VERSION ""

NS_ :

BS_:

BU_: Canoe_Debug

BO_ 161 Phase1_Temp_Readings_0x0A1: 8 Vector__XXX
 SG_ tempPhase1_LEFT : 0|32@1- (1,0) [0|0] ""  Canoe_Debug
 SG_ tempPhase1_RIGHT : 32|32@1- (1,0) [0|0] ""  Canoe_Debug

BO_ 162 Phase2_Temp_Readings_0x0A2: 8 Vector__XXX
 SG_ tempPhase2_LEFT : 0|32@1- (1,0) [0|0] ""  Canoe_Debug
 SG_ tempPhase2_RIGHT : 32|32@1- (1,0) [0|0] ""  Canoe_Debug

BO_ 163 V12_Voltage_Phase1_Readings_0x0A3: 8 Vector__XXX
 SG_ voltage12V_bat1_phase1 : 0|32@1- (1,0) [0|0] ""  Canoe_Debug
 SG_ voltage12V_bat2_phase1 : 32|32@1- (1,0) [0|0] ""  Canoe_Debug

BO_ 164 V12_Voltage_Phase2_Readings_0x0A4: 8 Vector__XXX
 SG_ voltage12V_bat1_phase2 : 0|32@1- (1,0) [0|0] ""  Canoe_Debug
 SG_ voltage12V_bat2_phase2 : 32|32@1- (1,0) [0|0] ""  Canoe_Debug

BO_ 165 Phase1_Current_Readings_0X0A5: 8 Vector__XXX
 SG_ current_ph1_in : 0|32@1- (1,0) [0|0] ""  Canoe_Debug
 SG_ current_ph1_out : 32|32@1- (1,0) [0|0] ""  Canoe_Debug

BO_ 166 Phase2_Current_Readings_0X0A6: 8 Vector__XXX
 SG_ current_ph2_in : 0|32@1- (1,0) [0|0] ""  Canoe_Debug
 SG_ current_ph2_out : 32|32@1- (1,0) [0|0] ""  Canoe_Debug

BO_ 167 Power_Reading_0x0A7: 8 Vector__XXX
 SG_ power12V_phase1 : 0|32@1- (1,0) [0|0] ""  Canoe_Debug
 SG_ power12V_phase2 : 32|32@1- (1,0) [0|0] ""  Canoe_Debug

BO_ 168 Efficieny_0x0A8: 4 Vector__XXX
 SG_ efficiency : 0|32@1- (1,0) [0|0] ""  Canoe_Debug

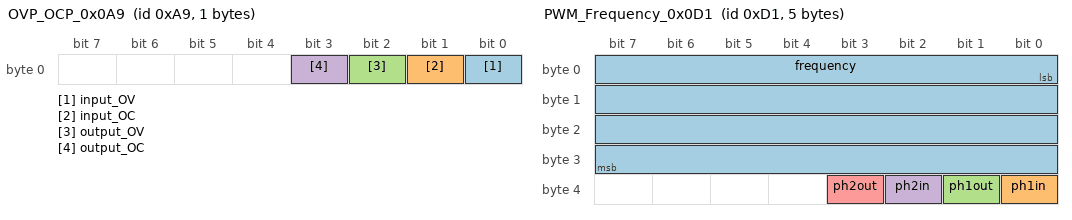
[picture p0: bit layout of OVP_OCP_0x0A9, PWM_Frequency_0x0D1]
BO_ 169 OVP_OCP_0x0A9: 1 Vector__XXX
 SG_ input_OV : 0|1@1+ (1,0) [0|0] ""  Canoe_Debug
 SG_ input_OC : 1|1@1+ (1,0) [0|0] ""  Canoe_Debug
 SG_ output_OV : 2|1@1+ (1,0) [0|0] ""  Canoe_Debug
 SG_ output_OC : 3|1@1+ (1,0) [0|0] ""  Canoe_Debug

BO_ 209 PWM_Frequency_0x0D1: 5 Canoe_Debug
 SG_ frequency : 0|32@1- (1,0) [0|0] "" Vector__XXX
 SG_ ph1in : 32|1@1+ (1,0) [0|0] "" Vector__XXX
 SG_ ph1out : 33|1@1+ (1,0) [0|0] "" Vector__XXX
 SG_ ph2in : 34|1@1+ (1,0) [0|0] "" Vector__XXX
 SG_ ph2out : 35|1@1+ (1,0) [0|0] "" Vector__XXX

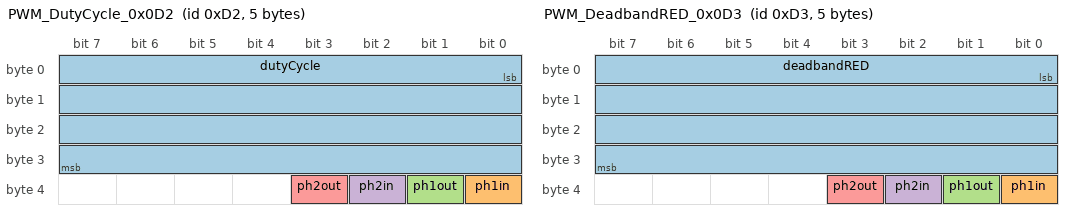
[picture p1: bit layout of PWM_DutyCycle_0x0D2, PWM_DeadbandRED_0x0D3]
BO_ 210 PWM_DutyCycle_0x0D2: 5 Canoe_Debug
 SG_ dutyCycle : 0|32@1- (1,0) [0|0] "" Vector__XXX
 SG_ ph1in : 32|1@1+ (1,0) [0|0] "" Vector__XXX
 SG_ ph1out : 33|1@1+ (1,0) [0|0] "" Vector__XXX
 SG_ ph2in : 34|1@1+ (1,0) [0|0] "" Vector__XXX
 SG_ ph2out : 35|1@1+ (1,0) [0|0] "" Vector__XXX

BO_ 211 PWM_DeadbandRED_0x0D3: 5 Canoe_Debug
 SG_ deadbandRED : 0|32@1- (1,0) [0|0] "" Vector__XXX
 SG_ ph1in : 32|1@1+ (1,0) [0|0] "" Vector__XXX
 SG_ ph1out : 33|1@1+ (1,0) [0|0] "" Vector__XXX
 SG_ ph2in : 34|1@1+ (1,0) [0|0] "" Vector__XXX
 SG_ ph2out : 35|1@1+ (1,0) [0|0] "" Vector__XXX

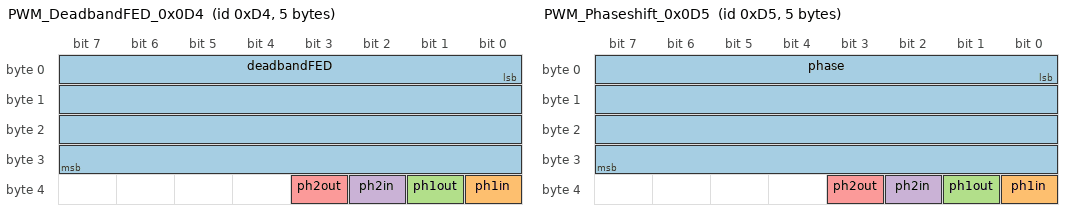
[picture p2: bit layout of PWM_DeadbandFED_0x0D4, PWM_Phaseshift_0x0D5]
BO_ 212 PWM_DeadbandFED_0x0D4: 5 Canoe_Debug
 SG_ deadbandFED : 0|32@1- (1,0) [0|0] "" Vector__XXX
 SG_ ph1in : 32|1@1+ (1,0) [0|0] "" Vector__XXX
 SG_ ph1out : 33|1@1+ (1,0) [0|0] "" Vector__XXX
 SG_ ph2in : 34|1@1+ (1,0) [0|0] "" Vector__XXX
 SG_ ph2out : 35|1@1+ (1,0) [0|0] "" Vector__XXX

BO_ 213 PWM_Phaseshift_0x0D5: 5 Canoe_Debug
 SG_ phase : 0|32@1- (1,0) [0|0] "" Vector__XXX
 SG_ ph1in : 32|1@1+ (1,0) [0|0] "" Vector__XXX
 SG_ ph1out : 33|1@1+ (1,0) [0|0] "" Vector__XXX
 SG_ ph2in : 34|1@1+ (1,0) [0|0] "" Vector__XXX
 SG_ ph2out : 35|1@1+ (1,0) [0|0] "" Vector__XXX

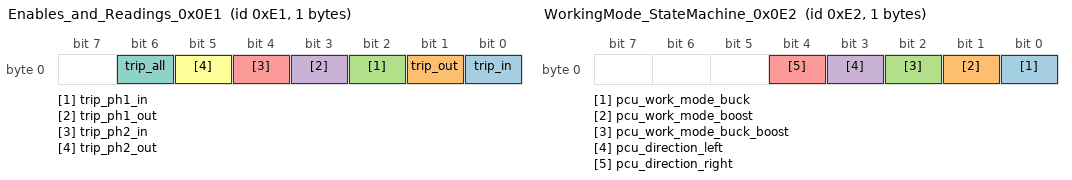
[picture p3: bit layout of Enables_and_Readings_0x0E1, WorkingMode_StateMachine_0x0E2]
BO_ 225 Enables_and_Readings_0x0E1: 1 Canoe_Debug
 SG_ trip_in : 0|1@1+ (1,0) [0|0] "" Vector__XXX
 SG_ trip_out : 1|1@1+ (1,0) [0|0] "" Vector__XXX
 SG_ trip_ph1_in : 2|1@1+ (1,0) [0|0] "" Vector__XXX
 SG_ trip_ph1_out : 3|1@1+ (1,0) [0|0] "" Vector__XXX
 SG_ trip_ph2_in : 4|1@1+ (1,0) [0|0] "" Vector__XXX
 SG_ trip_ph2_out : 5|1@1+ (1,0) [0|0] "" Vector__XXX
 SG_ trip_all : 6|1@1+ (1,0) [0|0] "" Vector__XXX

BO_ 226 WorkingMode_StateMachine_0x0E2: 1 Canoe_Debug
 SG_ pcu_work_mode_buck : 0|1@1+ (1,0) [0|0] "" Vector__XXX
 SG_ pcu_work_mode_boost : 1|1@1+ (1,0) [0|0] "" Vector__XXX
 SG_ pcu_work_mode_buck_boost : 2|1@1+ (1,0) [0|0] "" Vector__XXX
 SG_ pcu_direction_left : 3|1@1+ (1,0) [0|0] "" Vector__XXX
 SG_ pcu_direction_right : 4|1@1+ (1,0) [0|0] "" Vector__XXX

BA_DEF_  "BusType" STRING ;
BA_DEF_DEF_  "BusType" "";
BA_ "BusType" "CAN";
SIG_VALTYPE_ 161 tempPhase1_LEFT : 1;
SIG_VALTYPE_ 161 tempPhase1_RIGHT : 1;
SIG_VALTYPE_ 162 tempPhase2_LEFT : 1;
SIG_VALTYPE_ 162 tempPhase2_RIGHT : 1;
SIG_VALTYPE_ 163 voltage12V_bat1_phase1 : 1;
SIG_VALTYPE_ 163 voltage12V_bat2_phase1 : 1;
SIG_VALTYPE_ 164 voltage12V_bat1_phase2 : 1;
SIG_VALTYPE_ 164 voltage12V_bat2_phase2 : 1;
SIG_VALTYPE_ 165 current_ph1_in : 1;
SIG_VALTYPE_ 165 current_ph1_out : 1;
SIG_VALTYPE_ 166 current_ph2_in : 1;
SIG_VALTYPE_ 166 current_ph2_out : 1;
SIG_VALTYPE_ 167 power12V_phase1 : 1;
SIG_VALTYPE_ 167 power12V_phase2 : 1;
SIG_VALTYPE_ 168 efficiency : 1;
SIG_VALTYPE_ 209 frequency : 1;
SIG_VALTYPE_ 210 dutyCycle : 1;
SIG_VALTYPE_ 211 deadbandRED : 1;
SIG_VALTYPE_ 212 deadbandFED : 1;
SIG_VALTYPE_ 213 phase : 1;
